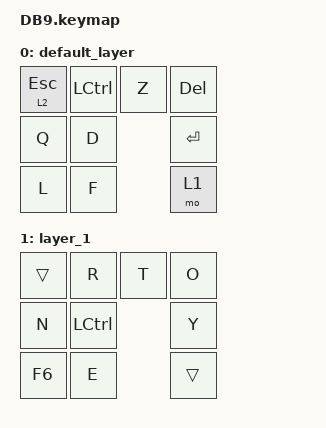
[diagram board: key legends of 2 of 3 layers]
#include <behaviors.dtsi>
#include <dt-bindings/zmk/keys.h>
#include <dt-bindings/zmk/bt.h>
#include <dt-bindings/zmk/bootloader.h> // Necessário para o &bootloader

/ {
    behaviors {
        // Comportamento para Camada 1 (Fusion Sketch)
        // Segura para &mo 1
        LH: layer_hold {
            compatible = "zmk,behavior-hold-tap";
            label = "LAYER_HOLD";
            #binding-cells = <2>;
            tapping-term-ms = <200>;
            bindings = <&mo>, <&kp>;
        };

        // Comportamento para Camada 2 (Bluetooth)
        // Segura para &mo 2, Toca para &kp ESC
        LH_BT: layer_hold_bt {
            compatible = "zmk,behavior-hold-tap";
            label = "LAYER_HOLD_BT";
            #binding-cells = <2>;
            tapping-term-ms = <200>;
            bindings = <&mo>, <&kp>;
        };
    };

    keymap {
        compatible = "zmk,keymap";

        // --- Camada 0: Padrão (Híbrida) ---
        default_layer {
            bindings = <
                &LH_BT 2 ESC    &kp LCTRL Z     &kp DEL
                &kp Q           &kp D           &kp RET  // RET = Enter
                &kp L           &kp F           &mo 1    // Segure para ativar a Camada 1
            >;
        };

        // --- Camada 1: Sketch Avançado ---
        layer_1 {
            bindings = <
                &trans          &kp R           &kp T
                &kp O           &kp N           &kp LCTRL Y // 'I' (Measure) virou 'N' (Look At)
                &kp F6          &kp E           &trans      // 'S' (Sketch) virou 'F6' (Home View)
            >;
        };

        // --- Camada 2: Bluetooth (Seu layout) ---
        layer_2 {
            bindings = <
                &trans          &none           &bootloader // &trans no gatilho
                &none           &none           &bt BT_CLR
                &bt BT_SEL 0    &bt BT_SEL 1    &bt BT_SEL 2
            >;
        };
    };
};
